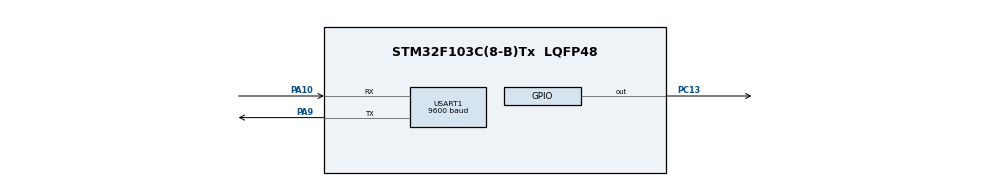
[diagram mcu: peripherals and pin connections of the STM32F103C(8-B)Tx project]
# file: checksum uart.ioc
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Mcu.Family=STM32F1
Mcu.Name=STM32F103C(8-B)Tx
Mcu.Package=LQFP48
NVIC.PriorityGroup=NVIC_PRIORITYGROUP_4
PA10.Mode=Asynchronous
PA10.Signal=USART1_RX
PA13.Mode=Serial_Wire
PA13.Signal=SYS_JTMS-SWDIO
PA14.Mode=Serial_Wire
PA14.Signal=SYS_JTCK-SWCLK
PA9.Mode=Asynchronous
PA9.Signal=USART1_TX
PC13-TAMPER-RTC.Signal=GPIO_Output
ProjectManager.HeapSize=0x200
ProjectManager.StackSize=0x400
ProjectManager.TargetToolchain=STM32CubeIDE
RCC.APB1Freq_Value=8000000
RCC.APB2Freq_Value=8000000
USART1.BaudRate=9600
USART1.VirtualMode=VM_ASYNC
board=custom

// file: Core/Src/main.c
/* USER CODE BEGIN Header */
/**
  ******************************************************************************
  * @file           : main.c
  * @brief          : Main program body
  ******************************************************************************
  * @attention
  *
  * Copyright (c) 2025 STMicroelectronics.
  * All rights reserved.
  *
  ******************************************************************************
  */
/* USER CODE END Header */
#include "main.h"

UART_HandleTypeDef huart1;

void SystemClock_Config(void);
static void MX_GPIO_Init(void);
static void MX_USART1_UART_Init(void);
/* USER CODE BEGIN PFP */
void UART_SendPacket(uint8_t *data, uint8_t length);
uint8_t UART_ReceivePacket(uint8_t *data);
/* USER CODE END PFP */

int main(void)
{

  /* MCU Configuration--------------------------------------------------------*/

  /* Reset of all peripherals, Initializes the Flash interface and the Systick. */
  HAL_Init();

  /* Configure the system clock */
  SystemClock_Config();

  /* Initialize all configured peripherals */
  MX_GPIO_Init();
  MX_USART1_UART_Init();
  /* USER CODE BEGIN 2 */
  // Pastikan LED OFF saat start (PC13 active low -> SET = OFF)
  HAL_GPIO_WritePin(GPIOC, GPIO_PIN_13, GPIO_PIN_SET);
  /* USER CODE END 2 */

  /* Infinite loop */
  /* USER CODE BEGIN WHILE */
  while (1)
  {
    uint8_t rxData[64];

    // Cek apakah ada paket masuk yang valid
    if (UART_ReceivePacket(rxData)) {
      // Cek command LED_ON (6 byte)
      if (strncmp((char*)rxData, "LED_ON", 6) == 0) {
        HAL_GPIO_WritePin(GPIOC, GPIO_PIN_13, GPIO_PIN_RESET); // LED ON (active low)
        // Optional: kirim acknowledgement
        const char ack[] = "ACK_ON";
        UART_SendPacket((uint8_t*)ack, (uint8_t)strlen(ack));
      }
      // Cek command LED_OFF (7 byte)
      else if (strncmp((char*)rxData, "LED_OFF", 7) == 0) {
        HAL_GPIO_WritePin(GPIOC, GPIO_PIN_13, GPIO_PIN_SET); // LED OFF
        const char ack[] = "ACK_OFF";
        UART_SendPacket((uint8_t*)ack, (uint8_t)strlen(ack));
      }
      // Kamu bisa tambahkan parsing command lain di sini
    }

    // singgah sebentar agar tidak full CPU
    HAL_Delay(5);
  }
    /* USER CODE END WHILE */

}

void SystemClock_Config(void)
{
  RCC_OscInitTypeDef RCC_OscInitStruct = {0};
  RCC_ClkInitTypeDef RCC_ClkInitStruct = {0};

  /** Initializes the RCC Oscillators according to the specified parameters
  * in the RCC_OscInitTypeDef structure.
  */
  RCC_OscInitStruct.OscillatorType = RCC_OSCILLATORTYPE_HSI;
  RCC_OscInitStruct.HSIState = RCC_HSI_ON;
  RCC_OscInitStruct.HSICalibrationValue = RCC_HSICALIBRATION_DEFAULT;
  RCC_OscInitStruct.PLL.PLLState = RCC_PLL_NONE;
  if (HAL_RCC_OscConfig(&RCC_OscInitStruct) != HAL_OK)
  {
    Error_Handler();
  }

  /** Initializes the CPU, AHB and APB buses clocks
  */
  RCC_ClkInitStruct.ClockType = RCC_CLOCKTYPE_HCLK|RCC_CLOCKTYPE_SYSCLK
                              |RCC_CLOCKTYPE_PCLK1|RCC_CLOCKTYPE_PCLK2;
  RCC_ClkInitStruct.SYSCLKSource = RCC_SYSCLKSOURCE_HSI;
  RCC_ClkInitStruct.AHBCLKDivider = RCC_SYSCLK_DIV1;
  RCC_ClkInitStruct.APB1CLKDivider = RCC_HCLK_DIV1;
  RCC_ClkInitStruct.APB2CLKDivider = RCC_HCLK_DIV1;

  if (HAL_RCC_ClockConfig(&RCC_ClkInitStruct, FLASH_LATENCY_0) != HAL_OK)
  {
    Error_Handler();
  }
}

static void MX_USART1_UART_Init(void)
{

  huart1.Instance = USART1;
  huart1.Init.BaudRate = 9600;
  huart1.Init.WordLength = UART_WORDLENGTH_8B;
  huart1.Init.StopBits = UART_STOPBITS_1;
  huart1.Init.Parity = UART_PARITY_NONE;
  huart1.Init.Mode = UART_MODE_TX_RX;
  huart1.Init.HwFlowCtl = UART_HWCONTROL_NONE;
  huart1.Init.OverSampling = UART_OVERSAMPLING_16;
  if (HAL_UART_Init(&huart1) != HAL_OK)
  {
    Error_Handler();
  }

}

static void MX_GPIO_Init(void)
{
  GPIO_InitTypeDef GPIO_InitStruct = {0};

  /* GPIO Ports Clock Enable */
  __HAL_RCC_GPIOC_CLK_ENABLE();
  __HAL_RCC_GPIOA_CLK_ENABLE();

  /*Configure GPIO pin Output Level */
  HAL_GPIO_WritePin(GPIOC, GPIO_PIN_13, GPIO_PIN_RESET);

  /*Configure GPIO pin : PC13 */
  GPIO_InitStruct.Pin = GPIO_PIN_13;
  GPIO_InitStruct.Mode = GPIO_MODE_OUTPUT_PP;
  GPIO_InitStruct.Pull = GPIO_NOPULL;
  GPIO_InitStruct.Speed = GPIO_SPEED_FREQ_LOW;
  HAL_GPIO_Init(GPIOC, &GPIO_InitStruct);

}

/* USER CODE BEGIN 4 */

/**
 * @brief Kirim paket serial sesuai format: [0xAA][len][payload...][checksum]
 * @param data Pointer ke payload
 * @param length panjang payload (byte)
 */
void UART_SendPacket(uint8_t *data, uint8_t length) {
    uint8_t buffer[260];
    uint8_t checksum = 0;

    buffer[0] = 0xAA;       // Start byte
    buffer[1] = length;     // Panjang data

    for (uint8_t i = 0; i < length; i++) {
        buffer[2 + i] = data[i];
        checksum += data[i];
    }

    buffer[2 + length] = checksum; // checksum

    HAL_UART_Transmit(&huart1, buffer, (uint16_t)(length + 3), HAL_MAX_DELAY);
}

/**
 * @brief Menerima 1 paket sesuai format [0xAA][len][payload][checksum]
 * @param data Buffer untuk menyimpan payload (harus cukup besar)
 * @retval 1 jika paket valid diterima, 0 jika tidak ada paket / invalid
 *
 * Note: fungsi ini bersifat blocking singkat (menggunakan timeout kecil).
 */
uint8_t UART_ReceivePacket(uint8_t *data) {
    uint8_t start;
    // Baca 1 byte untuk mencari Start Byte (timeout kecil)
    if (HAL_UART_Receive(&huart1, &start, 1, 50) != HAL_OK) return 0;
    if (start != 0xAA) return 0;

    uint8_t length;
    if (HAL_UART_Receive(&huart1, &length, 1, 50) != HAL_OK) return 0;
    if (length == 0 || length > 200) return 0; // sanity check

    // Baca payload
    if (HAL_UART_Receive(&huart1, data, length, 200) != HAL_OK) return 0;

    uint8_t checksum;
    if (HAL_UART_Receive(&huart1, &checksum, 1, 50) != HAL_OK) return 0;

    uint8_t calc = 0;
    for (uint8_t i = 0; i < length; i++) calc += data[i];

    return (checksum == calc);
}

/* USER CODE END 4 */

void Error_Handler(void)
{
  __disable_irq();
  while (1)
  {
  }
}
